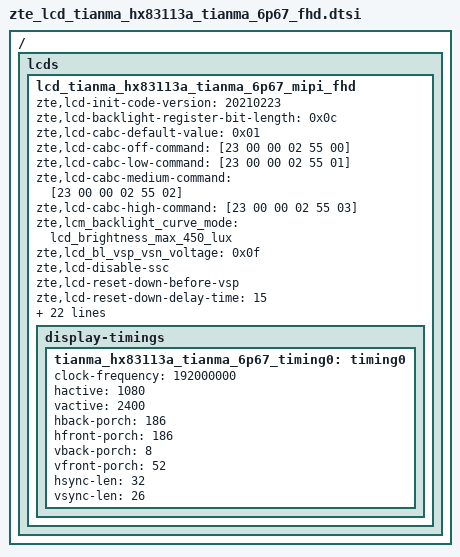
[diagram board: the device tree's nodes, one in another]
/ { lcds {
	lcd_tianma_hx83113a_tianma_6p67_mipi_fhd: lcd_tianma_hx83113a_tianma_6p67_mipi_fhd {
		zte,lcd-init-code-version = "20210223";
		zte,lcd-backlight-register-bit-length = <0x0c>;
		zte,lcd-cabc-default-value = <0x01>;
		zte,lcd-cabc-off-command = [23 00 00 02 55 00];
		zte,lcd-cabc-low-command = [23 00 00 02 55 01];
		zte,lcd-cabc-medium-command = [23 00 00 02 55 02];
		zte,lcd-cabc-high-command = [23 00 00 02 55 03];
		zte,lcm_backlight_curve_mode = "lcd_brightness_max_450_lux";
		zte,lcd_bl_vsp_vsn_voltage = <0x0f>;
		zte,lcd-disable-ssc;
		zte,lcd-reset-down-before-vsp;
		zte,lcd-reset-down-delay-time = <15>;
		zte,panel-name = "lcd_tianma_hx83113a_tianma_6p67_mipi_fhd";

		sprd,dsi-work-mode = <1>; /* video burst mode*/
		sprd,dsi-lane-number = <4>;
		sprd,dsi-color-format = "rgb888";

		sprd,phy-bit-clock = <1280000>;  /* kbps */
		sprd,phy-escape-clock = <20000>;/* kHz */

		sprd,width-mm = <69498>;
		sprd,height-mm = <154440>;

		sprd,esd-check-enable = <1>;/* 0:close , 1:open */
		sprd,esd-check-mode = <0>;/* 0:REG ,1:TE  */
		sprd,esd-check-period = <3000>;
		sprd,esd-check-register = <0x0A>;
		sprd,esd-check-value = <0x9D>;

		sprd,reset-on-sequence = <1 10>, <0 5>, <1 55>;
		sprd,reset-off-sequence = <1 5>;

		sprd,initial-command = [
			39 00 00 04 b9 83 11 3a
			39 00 00 02 bb 03
			39 00 00 02 35 00
			39 00 00 03 51 0F FF
			39 00 00 02 53 2C
			39 00 00 02 55 00
			05 78 00 01 11
			39 00 00 11 B2 00 33 88 90 60 00 20 32 00
						04 00 CE 11 11 00 00
			39 00 00 08 CB 5F 19 12 2D 00 EE 44
			39 00 00 1E E7 47 25 08 08 20 84 1E 84 00
						84 04 02 00 00 02 02 12 05 FF
						FF 1E 84 00 84 08 00 00 08 17
			39 05 00 27 D3 81 08 01 01 00 08 01 01 07
						01 1F 1F 09 09 09 09 20 04 32
						10 08 00 08 32 10 1E 00 1E 32
						10 07 00 07 00 00 22 09 82
			05 14 00 01 29
			];

		sprd,sleep-in-command = [
			13 14 00 01 28
			13 64 00 01 10
			39 00 00 04 B9 83 11 3A
			39 00 00 02 B1 4D
			];
		sprd,sleep-out-command = [
			13 78 00 01 11
			13 14 00 01 29
			];

		display-timings {
			tianma_hx83113a_tianma_6p67_timing0: timing0 {
				clock-frequency = <192000000>;
				hactive = <1080>;
				vactive = <2400>;
				hback-porch = <186>;
				hfront-porch = <186>;
				vback-porch = <8>;
				vfront-porch = <52>;
				hsync-len = <32>;
				vsync-len = <26>;
			};
		};

		/*oled-backlight {
			default-brightness-level = <1638>;
			sprd,max-level = <4095>;
			brightness-levels = [
				39 00 00 03 51 00 00
				39 00 00 02 53 2C
			];
		};*/
	};
}; };
